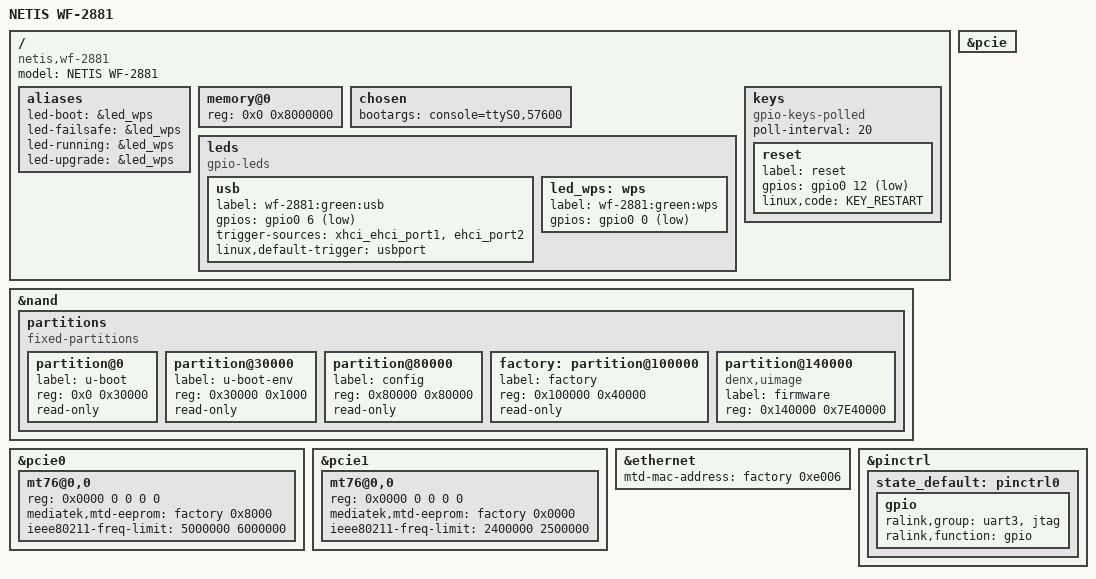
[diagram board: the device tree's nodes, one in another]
/dts-v1/;

#include "mt7621.dtsi"

#include <dt-bindings/gpio/gpio.h>
#include <dt-bindings/input/input.h>

/ {
	compatible = "netis,wf-2881", "mediatek,mt7621-soc";
	model = "NETIS WF-2881";

	aliases {
		led-boot = &led_wps;
		led-failsafe = &led_wps;
		led-running = &led_wps;
		led-upgrade = &led_wps;
	};

	memory@0 {
		device_type = "memory";
		reg = <0x0 0x8000000>;
	};

	chosen {
		bootargs = "console=ttyS0,57600";
	};

	leds {
		compatible = "gpio-leds";

		usb {
			label = "wf-2881:green:usb";
			gpios = <&gpio0 6 GPIO_ACTIVE_LOW>;
			trigger-sources = <&xhci_ehci_port1>, <&ehci_port2>;
			linux,default-trigger = "usbport";
		};

		led_wps: wps {
			label = "wf-2881:green:wps";
			gpios = <&gpio0 0 GPIO_ACTIVE_LOW>;
		};
	};

	keys {
		compatible = "gpio-keys-polled";
		poll-interval = <20>;

		reset {
			label = "reset";
			gpios = <&gpio0 12 GPIO_ACTIVE_LOW>;
			linux,code = <KEY_RESTART>;
		};
	};
};

&nand {
	status = "okay";

	partitions {
		compatible = "fixed-partitions";
		#address-cells = <1>;
		#size-cells = <1>;

		partition@0 {
			label = "u-boot";
			reg = <0x0 0x30000>;
			read-only;
		};

		partition@30000 {
			label = "u-boot-env";
			reg = <0x30000 0x1000>;
			read-only;
		};

		partition@80000 {
			label = "config";
			reg = <0x80000 0x80000>;
			read-only;
		};

		factory: partition@100000 {
			label = "factory";
			reg = <0x100000 0x40000>;
			read-only;
		};

		partition@140000 {
			compatible = "denx,uimage";
			label = "firmware";
			reg = <0x140000 0x7E40000>;
		};
	};
};

&pcie {
	status = "okay";
};

&pcie0 {
	mt76@0,0 {
		reg = <0x0000 0 0 0 0>;
		mediatek,mtd-eeprom = <&factory 0x8000>;
		ieee80211-freq-limit = <5000000 6000000>;
	};
};

&pcie1 {
	mt76@0,0 {
		reg = <0x0000 0 0 0 0>;
		mediatek,mtd-eeprom = <&factory 0x0000>;
		ieee80211-freq-limit = <2400000 2500000>;
	};
};

&ethernet {
	mtd-mac-address = <&factory 0xe006>;
};

&pinctrl {
	state_default: pinctrl0 {
		gpio {
			ralink,group = "uart3", "jtag";
			ralink,function = "gpio";
		};
	};
};
